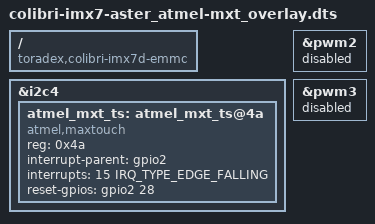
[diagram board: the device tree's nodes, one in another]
// Atmel touchscreen for the 7inch capacitive display orderable at Toradex. Use this devicetree on the Aster board.

/dts-v1/;
/plugin/;

#include <dt-bindings/gpio/gpio.h>
#include <dt-bindings/interrupt-controller/irq.h>

/ {
	compatible = "toradex,colibri-imx7d-emmc";
};

&i2c4 {
	#address-cells = <1>;
	#size-cells = <0>;

	atmel_mxt_ts: atmel_mxt_ts@4a {
		compatible = "atmel,maxtouch";
		reg = <0x4a>;
		interrupt-parent = <&gpio2>;
		interrupts = <15 IRQ_TYPE_EDGE_FALLING>;
		reset-gpios = <&gpio2 28 GPIO_ACTIVE_HIGH>;
		status = "okay";
	};
};

&pwm2 {
	status = "disabled";
};

&pwm3 {
	status = "disabled";
};
